# ESP32C3 register map
File version: 1.0
CPU: RISC-V RV32IMC single-core 1, little endian, no MPU, FPU, 3 interrupt priority bits
Registers are 32-bit, read-write, reset 0x0 unless marked. A register's access mark holds for its fields unless they carry their own. Offsets are from the block's base; [hi:lo] are bit positions; {n}, {i} and the like mark numbered series.

## SYS_TIMER
Base 0x60023000
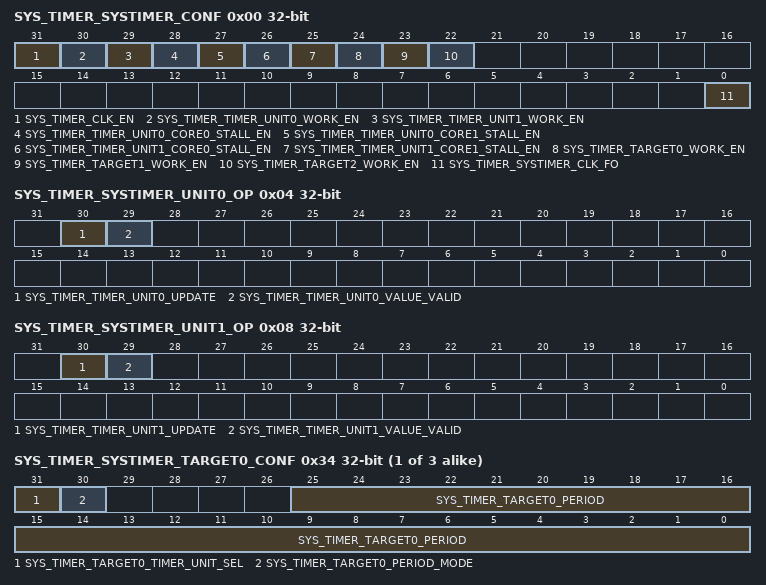
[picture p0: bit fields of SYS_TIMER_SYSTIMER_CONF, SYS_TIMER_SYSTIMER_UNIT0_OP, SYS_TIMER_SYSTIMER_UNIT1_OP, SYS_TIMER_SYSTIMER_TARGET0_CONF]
0x00 SYS_TIMER_SYSTIMER_CONF
  [31] SYS_TIMER_CLK_EN, [30] SYS_TIMER_TIMER_UNIT0_WORK_EN, [29] SYS_TIMER_TIMER_UNIT1_WORK_EN, [28] SYS_TIMER_TIMER_UNIT0_CORE0_STALL_EN, [27] SYS_TIMER_TIMER_UNIT0_CORE1_STALL_EN, [26] SYS_TIMER_TIMER_UNIT1_CORE0_STALL_EN, [25] SYS_TIMER_TIMER_UNIT1_CORE1_STALL_EN, [24] SYS_TIMER_TARGET0_WORK_EN, [23] SYS_TIMER_TARGET1_WORK_EN, [22] SYS_TIMER_TARGET2_WORK_EN, [0] SYS_TIMER_SYSTIMER_CLK_FO
0x04 SYS_TIMER_SYSTIMER_UNIT0_OP access per field
  [30] SYS_TIMER_TIMER_UNIT0_UPDATE wo, [29] SYS_TIMER_TIMER_UNIT0_VALUE_VALID rw
0x08 SYS_TIMER_SYSTIMER_UNIT1_OP access per field
  [30] SYS_TIMER_TIMER_UNIT1_UPDATE wo, [29] SYS_TIMER_TIMER_UNIT1_VALUE_VALID rw
0x0C SYS_TIMER_SYSTIMER_UNIT0_LOAD_HI
  [19:0] SYS_TIMER_TIMER_UNIT0_LOAD_HI
0x10 SYS_TIMER_SYSTIMER_UNIT0_LOAD_LO
  [31:0] SYS_TIMER_TIMER_UNIT0_LOAD_LO
0x14 SYS_TIMER_SYSTIMER_UNIT1_LOAD_HI
  [19:0] SYS_TIMER_TIMER_UNIT1_LOAD_HI
0x18 SYS_TIMER_SYSTIMER_UNIT1_LOAD_LO
  [31:0] SYS_TIMER_TIMER_UNIT1_LOAD_LO
{0x1C+8i} SYS_TIMER_SYSTIMER_TARGET{i}_HI (i=0..2)
  [19:0] SYS_TIMER_TIMER_TARGET{i}_HI
{0x20+8i} SYS_TIMER_SYSTIMER_TARGET{i}_LO (i=0..2)
  [31:0] SYS_TIMER_TIMER_TARGET{i}_LO
{0x34+4i} SYS_TIMER_SYSTIMER_TARGET{i}_CONF (i=0..2)
  [31] SYS_TIMER_TARGET{i}_TIMER_UNIT_SEL, [30] SYS_TIMER_TARGET{i}_PERIOD_MODE, [25:0] SYS_TIMER_TARGET{i}_PERIOD
0x40 SYS_TIMER_SYSTIMER_UNIT0_VALUE_HI ro
  [19:0] SYS_TIMER_TIMER_UNIT0_VALUE_HI
0x44 SYS_TIMER_SYSTIMER_UNIT0_VALUE_LO ro
  [31:0] SYS_TIMER_TIMER_UNIT0_VALUE_LO
0x48 SYS_TIMER_SYSTIMER_UNIT1_VALUE_HI ro
  [19:0] SYS_TIMER_TIMER_UNIT1_VALUE_HI
0x4C SYS_TIMER_SYSTIMER_UNIT1_VALUE_LO ro
  [31:0] SYS_TIMER_TIMER_UNIT1_VALUE_LO
{0x50+4i} SYS_TIMER_SYSTIMER_COMP{i}_LOAD wo (i=0..2)
  [0] SYS_TIMER_TIMER_COMP{i}_LOAD
0x5C SYS_TIMER_SYSTIMER_UNIT0_LOAD wo
  [0] SYS_TIMER_TIMER_UNIT0_LOAD
0x60 SYS_TIMER_SYSTIMER_UNIT1_LOAD wo
  [0] SYS_TIMER_TIMER_UNIT1_LOAD
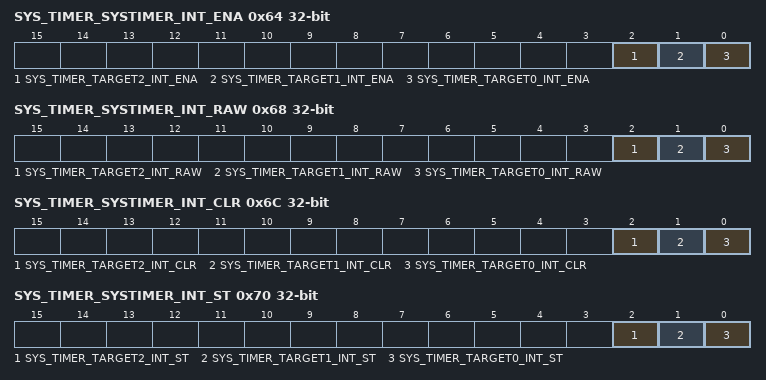
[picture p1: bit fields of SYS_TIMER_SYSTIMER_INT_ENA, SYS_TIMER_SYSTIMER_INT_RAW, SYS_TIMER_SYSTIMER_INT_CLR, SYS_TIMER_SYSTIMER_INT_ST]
0x64 SYS_TIMER_SYSTIMER_INT_ENA
  [2] SYS_TIMER_TARGET2_INT_ENA, [1] SYS_TIMER_TARGET1_INT_ENA, [0] SYS_TIMER_TARGET0_INT_ENA
0x68 SYS_TIMER_SYSTIMER_INT_RAW
  [2] SYS_TIMER_TARGET2_INT_RAW, [1] SYS_TIMER_TARGET1_INT_RAW, [0] SYS_TIMER_TARGET0_INT_RAW
0x6C SYS_TIMER_SYSTIMER_INT_CLR wo
  [2] SYS_TIMER_TARGET2_INT_CLR, [1] SYS_TIMER_TARGET1_INT_CLR, [0] SYS_TIMER_TARGET0_INT_CLR
0x70 SYS_TIMER_SYSTIMER_INT_ST ro
  [2] SYS_TIMER_TARGET2_INT_ST, [1] SYS_TIMER_TARGET1_INT_ST, [0] SYS_TIMER_TARGET0_INT_ST
0xFC SYS_TIMER_SYSTIMER_DATE
  [31:0] SYS_TIMER_DATE

## TIMG
Base 0x00000000
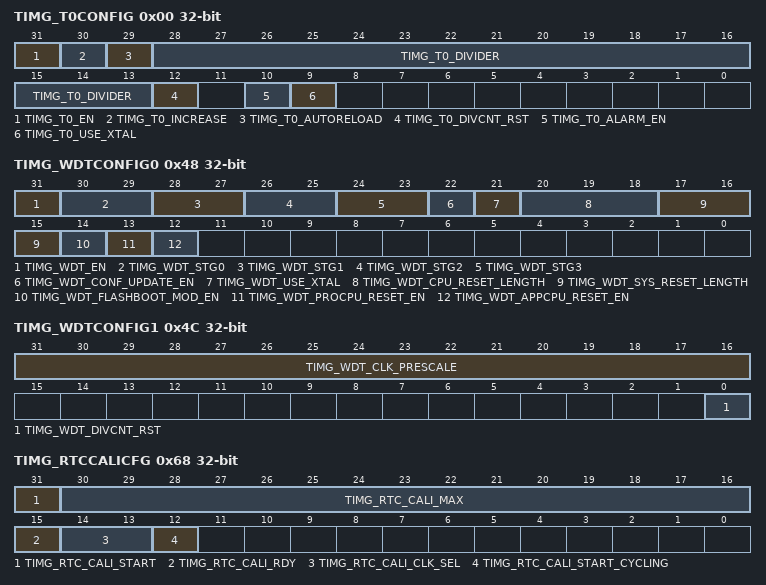
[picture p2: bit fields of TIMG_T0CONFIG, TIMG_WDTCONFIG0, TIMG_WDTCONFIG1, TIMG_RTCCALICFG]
0x00 TIMG_T0CONFIG access per field
  [31] TIMG_T0_EN rw, [30] TIMG_T0_INCREASE rw, [29] TIMG_T0_AUTORELOAD rw, [28:13] TIMG_T0_DIVIDER rw, [12] TIMG_T0_DIVCNT_RST wo, [10] TIMG_T0_ALARM_EN rw, [9] TIMG_T0_USE_XTAL rw
0x04 TIMG_T0LO ro
  [31:0] TIMG_T0_LO
0x08 TIMG_T0HI ro
  [21:0] TIMG_T0_HI
0x0C TIMG_T0UPDATE
  [31] TIMG_T0_UPDATE
0x10 TIMG_T0ALARMLO
  [31:0] TIMG_T0_ALARM_LO
0x14 TIMG_T0ALARMHI
  [21:0] TIMG_T0_ALARM_HI
0x18 TIMG_T0LOADLO
  [31:0] TIMG_T0_LOAD_LO
0x1C TIMG_T0LOADHI
  [21:0] TIMG_T0_LOAD_HI
0x20 TIMG_T0LOAD wo
  [31:0] TIMG_T0_LOAD
0x48 TIMG_WDTCONFIG0 access per field
  [31] TIMG_WDT_EN rw, [30-2n:29-2n] TIMG_WDT_STG{n} rw (n=0..3), [22] TIMG_WDT_CONF_UPDATE_EN wo, [21] TIMG_WDT_USE_XTAL rw, [20:18] TIMG_WDT_CPU_RESET_LENGTH rw, [17:15] TIMG_WDT_SYS_RESET_LENGTH rw, [14] TIMG_WDT_FLASHBOOT_MOD_EN rw, [13] TIMG_WDT_PROCPU_RESET_EN rw, [12] TIMG_WDT_APPCPU_RESET_EN rw
0x4C TIMG_WDTCONFIG1 access per field
  [31:16] TIMG_WDT_CLK_PRESCALE rw, [0] TIMG_WDT_DIVCNT_RST wo
{0x48+4i} TIMG_WDTCONFIG{i} (i=2..5)
  [31:0] TIMG_WDT_STG{i-2}_HOLD
0x60 TIMG_WDTFEED wo
  [31:0] TIMG_WDT_FEED
0x64 TIMG_WDTWPROTECT
  [31:0] TIMG_WDT_WKEY
0x68 TIMG_RTCCALICFG access per field
  [31] TIMG_RTC_CALI_START rw, [30:16] TIMG_RTC_CALI_MAX rw, [15] TIMG_RTC_CALI_RDY ro, [14:13] TIMG_RTC_CALI_CLK_SEL rw, [12] TIMG_RTC_CALI_START_CYCLING rw
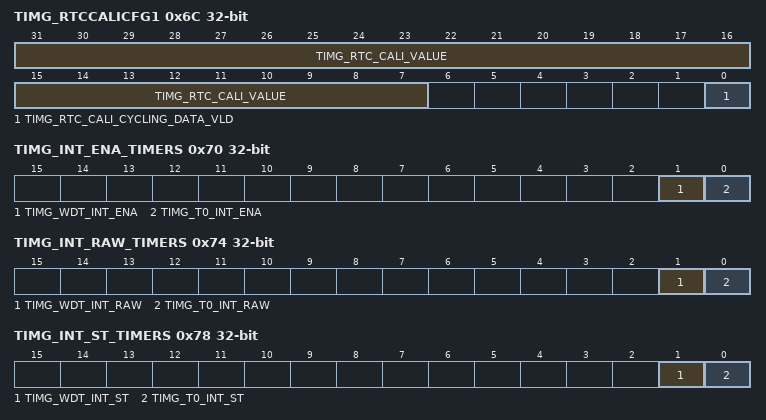
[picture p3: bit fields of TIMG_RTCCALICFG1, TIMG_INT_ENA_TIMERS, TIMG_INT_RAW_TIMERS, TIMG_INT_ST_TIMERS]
0x6C TIMG_RTCCALICFG1 ro
  [31:7] TIMG_RTC_CALI_VALUE, [0] TIMG_RTC_CALI_CYCLING_DATA_VLD
0x70 TIMG_INT_ENA_TIMERS
  [1] TIMG_WDT_INT_ENA, [0] TIMG_T0_INT_ENA
0x74 TIMG_INT_RAW_TIMERS
  [1] TIMG_WDT_INT_RAW, [0] TIMG_T0_INT_RAW
0x78 TIMG_INT_ST_TIMERS ro
  [1] TIMG_WDT_INT_ST, [0] TIMG_T0_INT_ST
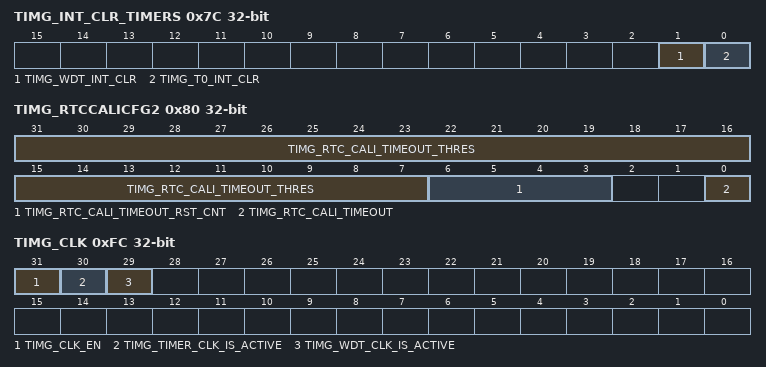
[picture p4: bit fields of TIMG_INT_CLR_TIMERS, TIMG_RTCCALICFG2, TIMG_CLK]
0x7C TIMG_INT_CLR_TIMERS wo
  [1] TIMG_WDT_INT_CLR, [0] TIMG_T0_INT_CLR
0x80 TIMG_RTCCALICFG2 access per field
  [31:7] TIMG_RTC_CALI_TIMEOUT_THRES rw, [6:3] TIMG_RTC_CALI_TIMEOUT_RST_CNT rw, [0] TIMG_RTC_CALI_TIMEOUT ro
0xF8 TIMG_NTIMERS_DATE
  [27:0] TIMG_NTIMERS_DATE
0xFC TIMG_CLK
  [31] TIMG_CLK_EN, [30] TIMG_TIMER_CLK_IS_ACTIVE, [29] TIMG_WDT_CLK_IS_ACTIVE

## UHCI
Base 0x00000000
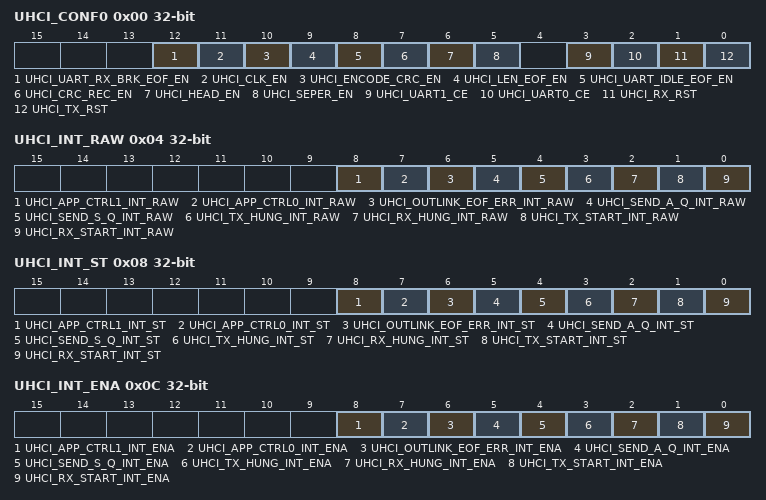
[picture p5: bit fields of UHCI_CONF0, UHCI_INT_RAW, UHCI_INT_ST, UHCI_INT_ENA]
0x00 UHCI_CONF0
  [12] UHCI_UART_RX_BRK_EOF_EN, [11] UHCI_CLK_EN, [10] UHCI_ENCODE_CRC_EN, [9] UHCI_LEN_EOF_EN, [8] UHCI_UART_IDLE_EOF_EN, [7] UHCI_CRC_REC_EN, [6] UHCI_HEAD_EN, [5] UHCI_SEPER_EN, [3] UHCI_UART1_CE, [2] UHCI_UART0_CE, [1] UHCI_RX_RST, [0] UHCI_TX_RST
0x04 UHCI_INT_RAW
  [8] UHCI_APP_CTRL1_INT_RAW, [7] UHCI_APP_CTRL0_INT_RAW, [6] UHCI_OUTLINK_EOF_ERR_INT_RAW, [5] UHCI_SEND_A_Q_INT_RAW, [4] UHCI_SEND_S_Q_INT_RAW, [3] UHCI_TX_HUNG_INT_RAW, [2] UHCI_RX_HUNG_INT_RAW, [1] UHCI_TX_START_INT_RAW, [0] UHCI_RX_START_INT_RAW
0x08 UHCI_INT_ST ro
  [8] UHCI_APP_CTRL1_INT_ST, [7] UHCI_APP_CTRL0_INT_ST, [6] UHCI_OUTLINK_EOF_ERR_INT_ST, [5] UHCI_SEND_A_Q_INT_ST, [4] UHCI_SEND_S_Q_INT_ST, [3] UHCI_TX_HUNG_INT_ST, [2] UHCI_RX_HUNG_INT_ST, [1] UHCI_TX_START_INT_ST, [0] UHCI_RX_START_INT_ST
0x0C UHCI_INT_ENA
  [8] UHCI_APP_CTRL1_INT_ENA, [7] UHCI_APP_CTRL0_INT_ENA, [6] UHCI_OUTLINK_EOF_ERR_INT_ENA, [5] UHCI_SEND_A_Q_INT_ENA, [4] UHCI_SEND_S_Q_INT_ENA, [3] UHCI_TX_HUNG_INT_ENA, [2] UHCI_RX_HUNG_INT_ENA, [1] UHCI_TX_START_INT_ENA, [0] UHCI_RX_START_INT_ENA
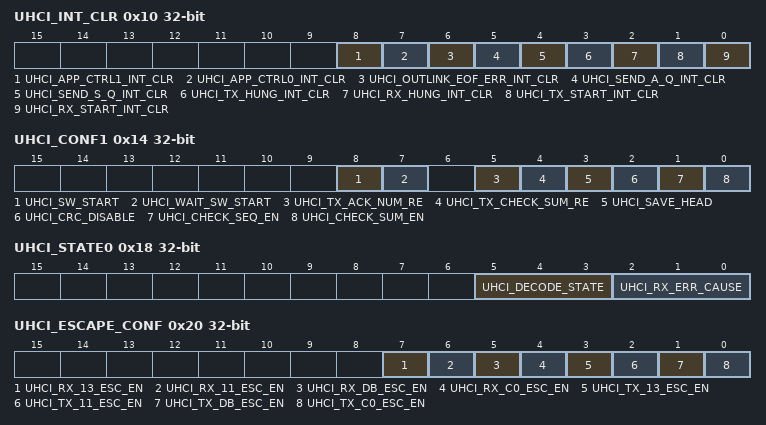
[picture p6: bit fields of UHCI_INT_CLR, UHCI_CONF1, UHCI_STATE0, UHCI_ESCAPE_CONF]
0x10 UHCI_INT_CLR wo
  [8] UHCI_APP_CTRL1_INT_CLR, [7] UHCI_APP_CTRL0_INT_CLR, [6] UHCI_OUTLINK_EOF_ERR_INT_CLR, [5] UHCI_SEND_A_Q_INT_CLR, [4] UHCI_SEND_S_Q_INT_CLR, [3] UHCI_TX_HUNG_INT_CLR, [2] UHCI_RX_HUNG_INT_CLR, [1] UHCI_TX_START_INT_CLR, [0] UHCI_RX_START_INT_CLR
0x14 UHCI_CONF1
  [8] UHCI_SW_START, [7] UHCI_WAIT_SW_START, [5] UHCI_TX_ACK_NUM_RE, [4] UHCI_TX_CHECK_SUM_RE, [3] UHCI_SAVE_HEAD, [2] UHCI_CRC_DISABLE, [1] UHCI_CHECK_SEQ_EN, [0] UHCI_CHECK_SUM_EN
0x18 UHCI_STATE0 ro
  [5:3] UHCI_DECODE_STATE, [2:0] UHCI_RX_ERR_CAUSE
0x1C UHCI_STATE1 ro
  [2:0] UHCI_ENCODE_STATE
0x20 UHCI_ESCAPE_CONF
  [7] UHCI_RX_13_ESC_EN, [6] UHCI_RX_11_ESC_EN, [5] UHCI_RX_DB_ESC_EN, [4] UHCI_RX_C0_ESC_EN, [3] UHCI_TX_13_ESC_EN, [2] UHCI_TX_11_ESC_EN, [1] UHCI_TX_DB_ESC_EN, [0] UHCI_TX_C0_ESC_EN
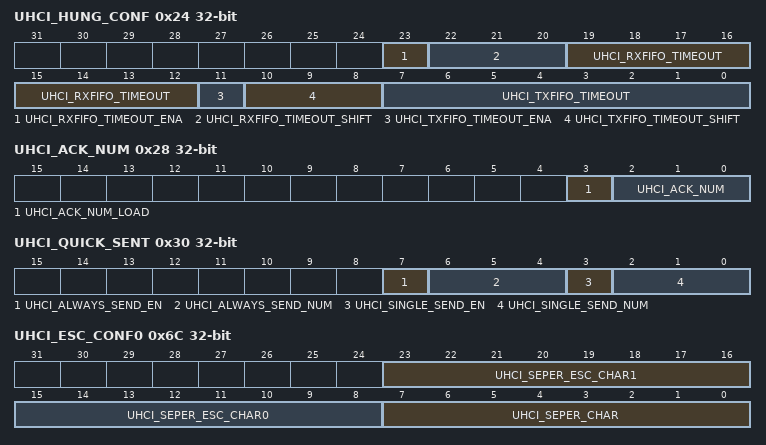
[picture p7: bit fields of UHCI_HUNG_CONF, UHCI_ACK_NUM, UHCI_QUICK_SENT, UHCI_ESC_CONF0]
0x24 UHCI_HUNG_CONF
  [23] UHCI_RXFIFO_TIMEOUT_ENA, [22:20] UHCI_RXFIFO_TIMEOUT_SHIFT, [19:12] UHCI_RXFIFO_TIMEOUT, [11] UHCI_TXFIFO_TIMEOUT_ENA, [10:8] UHCI_TXFIFO_TIMEOUT_SHIFT, [7:0] UHCI_TXFIFO_TIMEOUT
0x28 UHCI_ACK_NUM access per field
  [3] UHCI_ACK_NUM_LOAD wo, [2:0] UHCI_ACK_NUM rw
0x2C UHCI_RX_HEAD ro
0x30 UHCI_QUICK_SENT
  [7] UHCI_ALWAYS_SEND_EN, [6:4] UHCI_ALWAYS_SEND_NUM, [3] UHCI_SINGLE_SEND_EN, [2:0] UHCI_SINGLE_SEND_NUM
{0x34+8i} UHCI_Q{i}_WORD0 (i=0..6)
  [31:0] UHCI_SEND_Q{i}_WORD0
{0x38+8i} UHCI_Q{i}_WORD1 (i=0..6)
  [31:0] UHCI_SEND_Q{i}_WORD1
0x6C UHCI_ESC_CONF0
  [23:16] UHCI_SEPER_ESC_CHAR1, [15:8] UHCI_SEPER_ESC_CHAR0, [7:0] UHCI_SEPER_CHAR
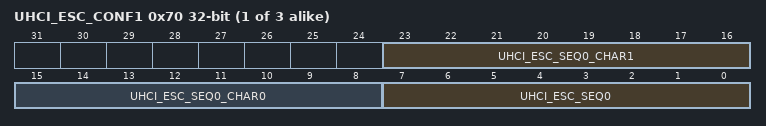
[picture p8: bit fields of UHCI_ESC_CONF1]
{0x6C+4i} UHCI_ESC_CONF{i} (i=1..3)
  [23:16] UHCI_ESC_SEQ{i-1}_CHAR1, [15:8] UHCI_ESC_SEQ{i-1}_CHAR0, [7:0] UHCI_ESC_SEQ{i-1}
0x7C UHCI_PKT_THRES
  [12:0] UHCI_PKT_THRS
0x80 UHCI_DATE
